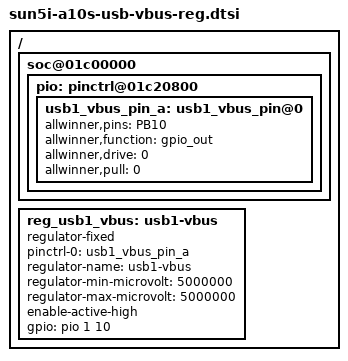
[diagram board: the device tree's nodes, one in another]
/*
 * sun5i a10s boards usb vbus supply common code
 *
 * Copyright 2014 - Hans de Goede <hdegoede@redhat.com>
 *
 * The code contained herein is licensed under the GNU General Public
 * License. You may obtain a copy of the GNU General Public License
 * Version 2 or later at the following locations:
 *
 * http://www.opensource.org/licenses/gpl-license.html
 * http://www.gnu.org/copyleft/gpl.html
 */

/ {
	soc@01c00000 {
		pio: pinctrl@01c20800 {
			usb1_vbus_pin_a: usb1_vbus_pin@0 {
				allwinner,pins = "PB10";
				allwinner,function = "gpio_out";
				allwinner,drive = <0>;
				allwinner,pull = <0>;
			};
		};
	};

	reg_usb1_vbus: usb1-vbus {
		compatible = "regulator-fixed";
		pinctrl-names = "default";
		pinctrl-0 = <&usb1_vbus_pin_a>;
		regulator-name = "usb1-vbus";
		regulator-min-microvolt = <5000000>;
		regulator-max-microvolt = <5000000>;
		enable-active-high;
		gpio = <&pio 1 10 0>;
	};
};
